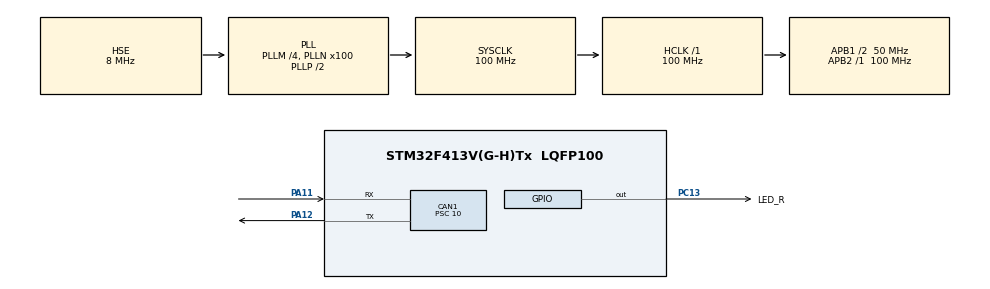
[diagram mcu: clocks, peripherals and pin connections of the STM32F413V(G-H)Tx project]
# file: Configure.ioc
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CAN1.BS1=CAN_BS1_2TQ
CAN1.BS2=CAN_BS2_2TQ
CAN1.CalculateBaudRate=1000000
CAN1.CalculateTimeBit=1000.00
CAN1.CalculateTimeQuantum=200.0
CAN1.Prescaler=10
Mcu.Family=STM32F4
Mcu.Name=STM32F413V(G-H)Tx
Mcu.Package=LQFP100
NVIC.CAN1_RX0_IRQn=true\:1\:0\:true\:false\:true\:true\:true
NVIC.CAN1_TX_IRQn=true\:1\:0\:true\:false\:true\:true\:true
NVIC.PriorityGroup=NVIC_PRIORITYGROUP_2
NVIC.TIM7_IRQn=true\:1\:1\:true\:false\:true\:true\:true
PA11.Mode=CAN_Activate
PA11.Signal=CAN1_RX
PA12.Mode=CAN_Activate
PA12.Signal=CAN1_TX
PA13.Mode=Serial_Wire
PA13.Signal=SYS_JTMS-SWDIO
PA14.Mode=Serial_Wire
PA14.Signal=SYS_JTCK-SWCLK
PC13.GPIO_Label=LED_R
PC13.Signal=GPIO_Output
PH0\ -\ OSC_IN.Mode=HSE-External-Oscillator
PH0\ -\ OSC_IN.Signal=RCC_OSC_IN
PH1\ -\ OSC_OUT.Mode=HSE-External-Oscillator
PH1\ -\ OSC_OUT.Signal=RCC_OSC_OUT
ProjectManager.HeapSize=0x200
ProjectManager.StackSize=0x400
ProjectManager.TargetToolchain=MDK-ARM V5.32
RCC.AHBFreq_Value=100000000
RCC.APB1CLKDivider=RCC_HCLK_DIV2
RCC.APB1Freq_Value=50000000
RCC.APB1TimFreq_Value=100000000
RCC.APB2Freq_Value=100000000
RCC.APB2TimFreq_Value=100000000
RCC.CortexFreq_Value=100000000
RCC.HCLKFreq_Value=100000000
RCC.HSE_VALUE=8000000
RCC.PLLM=4
RCC.PLLN=100
RCC.PLLSourceVirtual=RCC_PLLSOURCE_HSE
RCC.SYSCLKFreq_VALUE=100000000
RCC.SYSCLKSource=RCC_SYSCLKSOURCE_PLLCLK
RCC.USBFreq_Value=100000000
RCC.VCOOutputFreq_Value=200000000
TIM7.AutoReloadPreload=TIM_AUTORELOAD_PRELOAD_ENABLE
TIM7.Period=1000-1
TIM7.Prescaler=100-1
TIM7.TIM_MasterOutputTrigger=TIM_TRGO_ENABLE
VP_TIM7_VS_ClockSourceINT.Mode=Enable_Timer
board=custom

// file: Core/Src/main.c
/* USER CODE BEGIN Header */
/**
  ******************************************************************************
  * @file           : main.c
  * @brief          : Main program body
  ******************************************************************************
  * @attention
  *
  * <h2><center>&copy; Copyright (c) 2024 STMicroelectronics.
  * All rights reserved.</center></h2>
  *
  * This software component is licensed by ST under BSD 3-Clause license,
  * the "License"; You may not use this file except in compliance with the
  * License. You may obtain a copy of the License at:
  *                        opensource.org/licenses/BSD-3-Clause
  *
  ******************************************************************************
  */
/* USER CODE END Header */
#include "main.h"
#include "can.h"
#include "tim.h"
#include "gpio.h"

/* USER CODE BEGIN Includes */
#include "delay.h"
#include "interface_can.h"
/* USER CODE END Includes */

void SystemClock_Config(void);

int main(void)
{

  /* MCU Configuration--------------------------------------------------------*/

  /* Reset of all peripherals, Initializes the Flash interface and the Systick. */
  HAL_Init();

  /* Configure the system clock */
  SystemClock_Config();

  /* Initialize all configured peripherals */
  MX_GPIO_Init();
  MX_CAN1_Init();
  MX_TIM7_Init();
  /* USER CODE BEGIN 2 */
  delay_init(100);
  /*使能TIM7中断*/
  HAL_TIM_Base_Start_IT(&htim7);
  /*CAN1过滤器初始化*/
  CAN_Filter_Init();

  /*注:修改ID,进行校准等涉及内部参数更改的操作一般执行一次即可
    在循环中反复调用可能会出错,调用时请保证电机不在运行,否则可
	能会跑飞,由于驱动掉电存储使用的是内部flash,烧写时间较慢,同
	一驱动的不同参数更改最好间隔一段时间发送*/

  /*将节点ID为0x02的驱动ID改为0x06*/
  //set_blazer_node_id(0x02,6.0f);
  /*设置极对数为7*/
  //set_blazer_pole_pairs(0x02,7.0f);
  /*设置编码器型号*/
  //set_blazer_encoder_type(0x02,TLE5012B);
  /*设置最大电流为20A*/
  //set_blazer_max_current(0x02,20.0f);
  /*启动校准*/
  //set_blazer_calib(0x00,0.0f);
  //set_blazer_calib(0x01,0.0f);
  //set_blazer_calib(0x02,0.0f);
  set_blazer_calib(0x03,0.0f);
  /* USER CODE END 2 */

  /* Infinite loop */
  while (1)
  {

  }
}

void SystemClock_Config(void)
{
  RCC_OscInitTypeDef RCC_OscInitStruct = {0};
  RCC_ClkInitTypeDef RCC_ClkInitStruct = {0};

  /** Configure the main internal regulator output voltage
  */
  __HAL_RCC_PWR_CLK_ENABLE();
  __HAL_PWR_VOLTAGESCALING_CONFIG(PWR_REGULATOR_VOLTAGE_SCALE1);
  /** Initializes the RCC Oscillators according to the specified parameters
  * in the RCC_OscInitTypeDef structure.
  */
  RCC_OscInitStruct.OscillatorType = RCC_OSCILLATORTYPE_HSE;
  RCC_OscInitStruct.HSEState = RCC_HSE_ON;
  RCC_OscInitStruct.PLL.PLLState = RCC_PLL_ON;
  RCC_OscInitStruct.PLL.PLLSource = RCC_PLLSOURCE_HSE;
  RCC_OscInitStruct.PLL.PLLM = 4;
  RCC_OscInitStruct.PLL.PLLN = 100;
  RCC_OscInitStruct.PLL.PLLP = RCC_PLLP_DIV2;
  RCC_OscInitStruct.PLL.PLLQ = 2;
  RCC_OscInitStruct.PLL.PLLR = 2;
  if (HAL_RCC_OscConfig(&RCC_OscInitStruct) != HAL_OK)
  {
    Error_Handler();
  }
  /** Initializes the CPU, AHB and APB buses clocks
  */
  RCC_ClkInitStruct.ClockType = RCC_CLOCKTYPE_HCLK|RCC_CLOCKTYPE_SYSCLK
                              |RCC_CLOCKTYPE_PCLK1|RCC_CLOCKTYPE_PCLK2;
  RCC_ClkInitStruct.SYSCLKSource = RCC_SYSCLKSOURCE_PLLCLK;
  RCC_ClkInitStruct.AHBCLKDivider = RCC_SYSCLK_DIV1;
  RCC_ClkInitStruct.APB1CLKDivider = RCC_HCLK_DIV2;
  RCC_ClkInitStruct.APB2CLKDivider = RCC_HCLK_DIV1;

  if (HAL_RCC_ClockConfig(&RCC_ClkInitStruct, FLASH_LATENCY_3) != HAL_OK)
  {
    Error_Handler();
  }
}

void Error_Handler(void)
{
  __disable_irq();
  while (1)
  {
  }
}

/************************ (C) COPYRIGHT STMicroelectronics *****END OF FILE****/
